# f2838x_cm_ssi_regs register map
Vendor: Texas Instruments
Peripheral module from a debugger description file (folder C2000).
Address unit: 16 bits
Registers are 32-bit, read-only, no defined reset value unless marked. A register's access mark holds for its fields unless they carry their own. Offsets are as the file gives them; lines under a group give offsets from that group; [hi:lo] are bit positions; {n}, {i} and the like mark numbered series; 'fields as' and 'values as' point back to an identical list; <NAME> marks a mode.

## SSI_REGS — SSI Registers
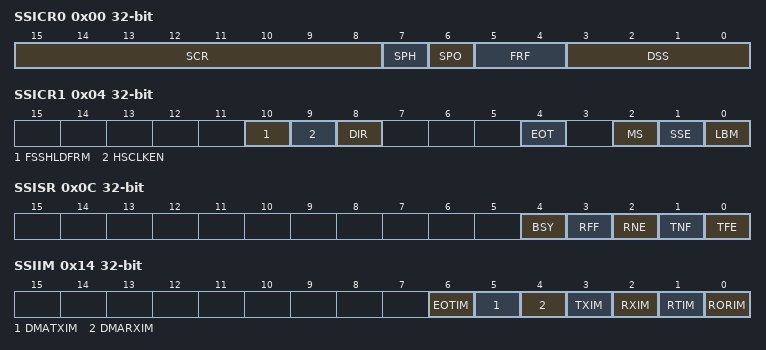
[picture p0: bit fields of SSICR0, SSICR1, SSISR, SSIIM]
0x00 SSICR0 rw — SSI Control 0
  [15:8] SCR — SSI Serial Clock Rate
  [7] SPH — SSI Serial clock PHase
  [6] SPO — SSI Serial clock POlarity
  [5:4] FRF — SSI FRame Format Select
  [3:0] DSS — SSI Data Size Select
0x04 SSICR1 rw — SSI Control 1
  [10] FSSHLDFRM — FSS Hold Frame
  [9] HSCLKEN — High Speed Clock Enable
  [8] DIR — SSI Direction of Operation
  [4] EOT — End of Transmission
  [2] MS — SSI Master/Slave Select
  [1] SSE — SSI Synchronous Serial Port Enable
  [0] LBM — SSI Loopback Mode
0x08 SSIDR rw — SSI Data
  [15:0] DATA — SSI Receive/Transmit Data
0x0C SSISR — SSI Status
  [4] BSY — SSI Busy Bit
  [3] RFF — SSI Receive FIFO Full
  [2] RNE — SSI Receive FIFO Not Empty
  [1] TNF — SSI Transmit FIFO Not Full
  [0] TFE — SSI Transmit FIFO Empty
0x10 SSICPSR rw — SSI Clock Prescale
  [7:0] CPSDVSR — SSI Clock Prescale Divisor
0x14 SSIIM rw — SSI Interrupt Mask
  [6] EOTIM — End of Transmit Interrupt Mask
  [5] DMATXIM — SSI Transmit DMA Interrupt Mask
  [4] DMARXIM — SSI Receive DMA Interrupt Mask
  [3] TXIM — SSI Transmit FIFO Interrupt Mask
  [2] RXIM — SSI Receive FIFO Interrupt Mask
  [1] RTIM — SSI Receive Time-Out Interrupt Mask
  [0] RORIM — SSI Receive Overrun Interrupt Mask
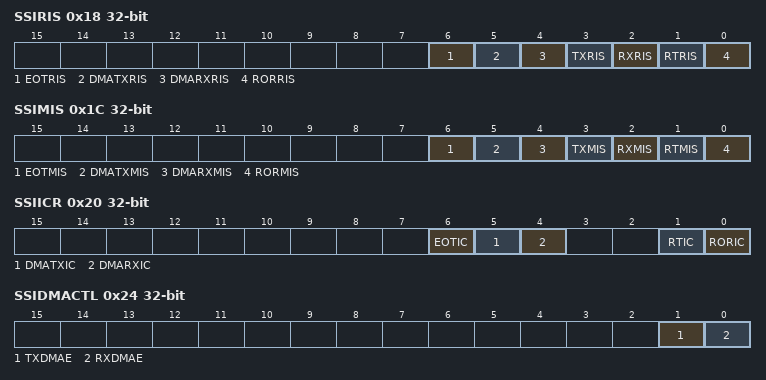
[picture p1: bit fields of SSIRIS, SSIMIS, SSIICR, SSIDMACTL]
0x18 SSIRIS — SSI Raw Interrupt Status
  [6] EOTRIS — End of Transmit Raw Interrupt Status
  [5] DMATXRIS — SSI Transmit DMA Raw Interrupt Status
  [4] DMARXRIS — SSI Receive DMA Raw Interrupt Status
  [3] TXRIS — SSI Transmit FIFO Raw Interrupt Status
  [2] RXRIS — SSI Receive FIFO Raw Interrupt Status
  [1] RTRIS — SSI Receive Time-Out Raw Interrupt Status
  [0] RORRIS — SSI Receive Overrun Raw Interrupt Status
0x1C SSIMIS — SSI Masked Interrupt Status
  [6] EOTMIS — End of Transmit Masked Interrupt Status
  [5] DMATXMIS — SSI Transmit DMA Masked Interrupt Status
  [4] DMARXMIS — SSI Receive DMA Masked Interrupt Status
  [3] TXMIS — SSI Transmit FIFO Masked Interrupt Status
  [2] RXMIS — SSI Receive FIFO Masked Interrupt Status
  [1] RTMIS — SSI Receive Time-Out Masked Interrupt Status
  [0] RORMIS — SSI Receive Overrun Masked Interrupt Status
0x20 SSIICR rw — SSI Interrupt Clear
  [6] EOTIC — End of Transmit Interrupt Clear
  [5] DMATXIC — SSI Transmit DMA Interrupt Clear
  [4] DMARXIC — SSI Receive DMA Interrupt Clear
  [1] RTIC — SSI Receive Time-Out Interrupt Clear
  [0] RORIC — SSI Receive Overrun Interrupt Clear
0x24 SSIDMACTL rw — SSI DMA Control
  [1] TXDMAE — Transmit DMA Enable
  [0] RXDMAE — Receive DMA Enable
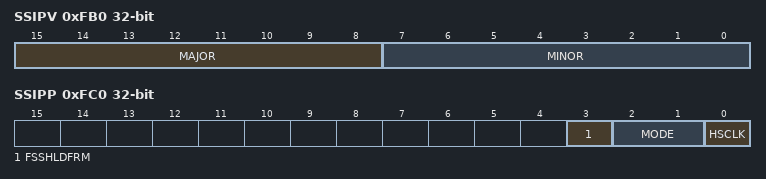
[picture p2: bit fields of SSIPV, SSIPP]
0xFB0 SSIPV — SSI Peripheral Version
  [15:8] MAJOR — Major Revision
  [7:0] MINOR — Minor Revision
0xFC0 SSIPP — SSI Peripheral Properties
  [3] FSSHLDFRM — SSInFss Hold Frame Capability
  [2:1] MODE — Mode of Operation
  [0] HSCLK — High Speed Capability
0xFC4 SSIPC access not given — SSI Peripheral Configuration
{0xFC0+4i} SSIPeriphID{i} (i=4..7) — SSI Peripheral Identification {i}
  [7:0] PID{i} — SSI Peripheral ID Register
{0xFE0+4i} SSIPeriphID{i} (i=0..3) — SSI Peripheral Identification {i}
  [7:0] PID{i} — SSI Peripheral ID Register
{0xFF0+4i} SSIPCellID{i} (i=0..3) — SSI PrimeCell Identification {i}
  [7:0] CID{i} — SSI PrimeCell ID Register
